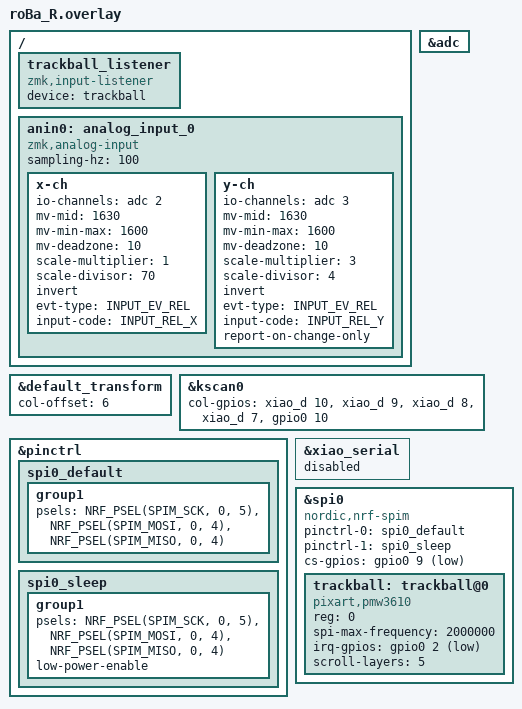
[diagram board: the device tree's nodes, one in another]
#include "roBa.dtsi"
#include <zephyr/dt-bindings/input/input-event-codes.h>
/* Reference: https://docs.zephyrproject.org/apidoc/latest/group__input__events.html */

// ADC を有効化
&adc {
	status = "okay";
};

&default_transform {
    col-offset = <6>;
};

&kscan0 {
        col-gpios
            = <&xiao_d 10 GPIO_ACTIVE_HIGH>
            , <&xiao_d 9 GPIO_ACTIVE_HIGH> 
            , <&xiao_d 8 GPIO_ACTIVE_HIGH> 
            , <&xiao_d 7 GPIO_ACTIVE_HIGH> 
            , <&gpio0 10 GPIO_ACTIVE_HIGH>
            ;
};

/ {
    trackball_listener {
        compatible = "zmk,input-listener";
        device = <&trackball>;

    };

    // ▼ ここから analog input driver のノードを追加
    anin0: analog_input_0 {
        compatible = "zmk,analog-input";
        sampling-hz = <100>;  // サンプリング周波数

        x-ch {
            io-channels = <&adc 2>;     // AIN2 (P0.04)
            mv-mid = <1630>;            // 中心値（例: 3.3V系ADCの半分）
            mv-min-max = <1600>;        // ±1.6V相当
            mv-deadzone = <10>;         // デッドゾーン
            scale-multiplier = <1>;
            scale-divisor = <70>;
            invert;
            evt-type = <INPUT_EV_REL>;
            input-code = <INPUT_REL_X>;
        };

        y-ch {
            io-channels = <&adc 3>;     // AIN3 (P0.05)
            mv-mid = <1630>;
            mv-min-max = <1600>;
            mv-deadzone = <10>;
            scale-multiplier = <3>;
            scale-divisor = <4>;
            invert;
            evt-type = <INPUT_EV_REL>;
            input-code = <INPUT_REL_Y>;
            report-on-change-only;
        };
    };
};

&pinctrl {
    spi0_default: spi0_default {
        group1 {
            psels = <NRF_PSEL(SPIM_SCK, 0, 5)>,
                <NRF_PSEL(SPIM_MOSI, 0, 4)>,
                <NRF_PSEL(SPIM_MISO, 0, 4)>;
        };
    };

    spi0_sleep: spi0_sleep {
        group1 {
            psels = <NRF_PSEL(SPIM_SCK, 0, 5)>,
                <NRF_PSEL(SPIM_MOSI, 0, 4)>,
                <NRF_PSEL(SPIM_MISO, 0, 4)>;
            low-power-enable;
        };
    };
};

&xiao_serial { status = "disabled"; };

&spi0 {
    status = "okay";
    compatible = "nordic,nrf-spim";
    pinctrl-0 = <&spi0_default>;
    pinctrl-1 = <&spi0_sleep>;
    pinctrl-names = "default", "sleep";
    cs-gpios = <&gpio0 9 GPIO_ACTIVE_LOW>;

    trackball: trackball@0 {
        status = "okay";
        compatible = "pixart,pmw3610";
        reg = <0>;
        spi-max-frequency = <2000000>;
        irq-gpios = <&gpio0 2 (GPIO_ACTIVE_LOW | GPIO_PULL_UP)>;
        // automouse-layer = <4>;  // この行を削除またはコメントアウト
        scroll-layers = <5>;
    };
};


